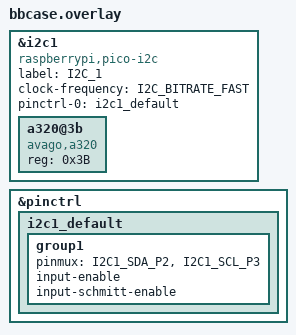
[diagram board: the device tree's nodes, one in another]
&i2c1 {
    a320@3b {
        compatible = "avago,a320";
        status = "okay";
        reg = <0x3B>;
    };
    
	label = "I2C_1";
	compatible = "raspberrypi,pico-i2c";
	status = "okay";
	clock-frequency = <I2C_BITRATE_FAST>; 
	pinctrl-0 = <&i2c1_default>;
	pinctrl-names = "default";
};

&pinctrl {
	i2c1_default: i2c1_default {
		group1 {
			pinmux = <I2C1_SDA_P2>, <I2C1_SCL_P3>;
			input-enable;
			input-schmitt-enable;
		};
	};
	
};
